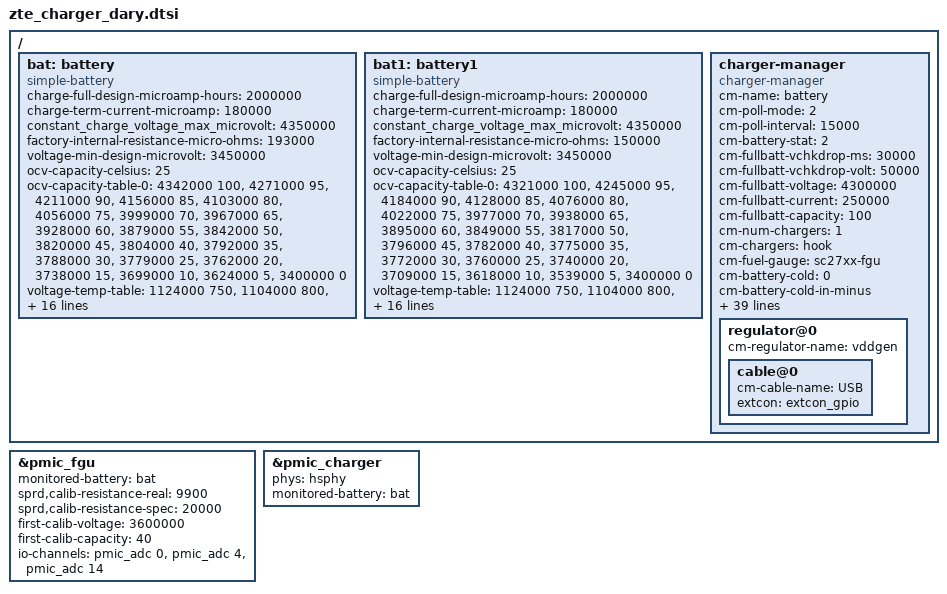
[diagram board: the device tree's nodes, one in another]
/ {
	bat: battery {
		compatible = "simple-battery";
		charge-full-design-microamp-hours = <2000000>;
		charge-term-current-microamp = <120000>;
		constant_charge_voltage_max_microvolt = <4350000>;
		factory-internal-resistance-micro-ohms = <320000>;
		voltage-min-design-microvolt = <3450000>;
		ocv-capacity-celsius = <20>;
		ocv-capacity-table-0 = <4330000 100>, <4249000 95>, <4189000 90>,
					<4133000 85>, <4081000 80>, <4034000 75>,
					<3991000 70>, <3953000 65>, <3910000 60>,
					<3866000 55>, <3836000 50>, <3813000 45>,
					<3795000 40>, <3782000 35>, <3774000 30>,
					<3765000 25>, <3750000 20>, <3726000 15>,
					<3687000 10>, <3658000 5>, <3400000 0>;
		voltage-temp-table = <1124000 750>, <1104000 800>, <1079000 850>,
					<1047000 900>, <1010000 950>, <967000 1000>,
					<917000 1050>, <861000 1100>, <801000 1150>,
					<738000 1200>, <672000 1250>, <607000 1300>,
					<543000 1350>, <482000 1400>, <425000 1450>,
					<372000 1500>, <325000 1550>, <282000 1600>,
					<243000 1650>, <208000 1700>, <178000 1750>;
		capacity-temp-table = <25 100>, <10 97>, <(-10) 60>;
		resistance-temp-table = <20 100>, <10 243>, <(-10) 468>;
		charge-sdp-current-microamp = <500000 500000>;
		charge-dcp-current-microamp = <1150000 3000000>;
		charge-cdp-current-microamp = <1150000 1150000>;
		charge-unknown-current-microamp = <500000 500000>;
	};

	bat1: battery1 {
		compatible = "simple-battery";
		charge-full-design-microamp-hours = <2000000>;
		charge-term-current-microamp = <120000>;
		constant_charge_voltage_max_microvolt = <4350000>;
		factory-internal-resistance-micro-ohms = <320000>;
		voltage-min-design-microvolt = <3450000>;
		ocv-capacity-celsius = <20>;
		ocv-capacity-table-0 = <4330000 100>, <4249000 95>, <4189000 90>,
					<4133000 85>, <4081000 80>, <4034000 75>,
					<3991000 70>, <3953000 65>, <3910000 60>,
					<3866000 55>, <3836000 50>, <3813000 45>,
					<3795000 40>, <3782000 35>, <3774000 30>,
					<3765000 25>, <3750000 20>, <3726000 15>,
					<3687000 10>, <3658000 5>, <3400000 0>;
		voltage-temp-table = <1124000 750>, <1104000 800>, <1079000 850>,
					<1047000 900>, <1010000 950>, <967000 1000>,
					<917000 1050>, <861000 1100>, <801000 1150>,
					<738000 1200>, <672000 1250>, <607000 1300>,
					<543000 1350>, <482000 1400>, <425000 1450>,
					<372000 1500>, <325000 1550>, <282000 1600>,
					<243000 1650>, <208000 1700>, <178000 1750>;
		capacity-temp-table = <25 100>, <10 97>, <(-10) 60>;
		resistance-temp-table = <20 100>, <10 243>, <(-10) 468>;
		charge-sdp-current-microamp = <500000 500000>;
		charge-dcp-current-microamp = <1150000 3000000>;
		charge-cdp-current-microamp = <1150000 1150000>;
		charge-unknown-current-microamp = <500000 500000>;
	};

	charger-manager {
		compatible = "charger-manager";
		cm-name = "battery";
		cm-poll-mode = <2>;
		cm-poll-interval = <15000>;
		cm-battery-stat = <2>;

		cm-fullbatt-vchkdrop-ms = <30000>;
		cm-fullbatt-vchkdrop-volt = <60000>;
		cm-fullbatt-voltage = <4330000>;
		cm-fullbatt-current = <120000>;
		cm-fullbatt-capacity = <100>;

		cm-num-chargers = <1>;
		cm-chargers = "fan54015_charger";
		cm-fuel-gauge = "sc27xx-fgu";

		/* in deci centigrade */
		cm-battery-cold = <200>;
		cm-battery-cold-in-minus;
		cm-battery-hot = <800>;
		cm-battery-temp-diff = <100>;

		/* Allow charging for 6hr */
		cm-charging-max = <21600000>;
		/* recovery charging after stop charging 45min */
		cm-discharging-max = <2700000>;

		/* the interval to feed charger watchdog */
		cm-wdt-interval = <60>;

		/* drop voltage in microVolts to allow shutdown */
		cm-shutdown-voltage = <3100000>;

		/* when 99% of the time is exceeded, it will be forced to 100% */
		cm-tickle-time-out = <1500>;

		/* how much time to allow capacity change */
		cm-one-cap-time = <30>;

		/* when the safe charging voltage is exceeded, stop charging */
		cm-charge-voltage-max = <6500000>;
		/* drop voltage in microVolts to restart charging */
		cm-charge-voltage-drop = <700000>;
		cm-dcp-jeita-temp-table = <1000 1030 0 4350000>, <1150 1180 700000 4350000>,
			<1450 1420 1150000 4350000>, <1600 1570 700000 4100000>;
		cm-sdp-jeita-temp-table = <1000 1030 0 4350000>, <1150 1180 500000 4350000>,
			<1450 1420 500000 4350000>, <1600 1570 500000 4100000>;
		cm-cdp-jeita-temp-table = <1000 1030 0 4350000>, <1150 1180 700000 4350000>,
			<1450 1420 1150000 4350000>, <1600 1570 700000 4100000>;
		cm-unknown-jeita-temp-table = <1000 1030 0 4350000>, <1150 1180 500000 4350000>,
			<1450 1420 500000 4350000>, <1600 1570 500000 4100000>;

		monitored-battery = <&bat>;
		cm-capacity-track;

		cm-cap-remap-table = <1 2 3>, <2 3 2>, <98 99 2>, <99 100 3>;

		regulator@0 {
			cm-regulator-name = "vddgen";
			cable@0 {
				cm-cable-name = "USB";
				extcon = <&extcon_gpio>;
			};
		};
	};
};

&bat {
	charge-full-design-microamp-hours = <2000000>;
	charge-term-current-microamp = <180000>;
	constant_charge_voltage_max_microvolt = <4350000>;
	constant_charge_current_max_microamp = <1000000>;
	factory-internal-resistance-micro-ohms = <193000>;
	voltage-min-design-microvolt = <3450000>;
	ocv-capacity-celsius = <25>;
	batt-id-list = <270>;  /* kohm, fenghua / weike */
	ocv-capacity-table-0 = <4342000 100>, <4271000 95>, <4211000 90>,
				<4156000 85>, <4103000 80>, <4056000 75>,
				<3999000 70>, <3967000 65>, <3928000 60>,
				<3879000 55>, <3842000 50>, <3820000 45>,
				<3804000 40>, <3792000 35>, <3788000 30>,
				<3779000 25>, <3762000 20>, <3738000 15>,
				<3699000 10>, <3624000 5>, <3400000 0>;
	/* NTC 100k, Vref 1850mV, R pull-up 110K, R pull-down 200k */
	voltage-temp-table = <1124000 750>, <1104000 800>, <1079000 850>,
				<1047000 900>, <1010000 950>, <967000 1000>,
				<917000 1050>, <861000 1100>, <801000 1150>,
				<738000 1200>, <672000 1250>, <607000 1300>,
				<543000 1350>, <482000 1400>, <425000 1450>,
				<372000 1500>, <325000 1550>, <282000 1600>,
				<243000 1650>, <208000 1700>, <178000 1750>;
	charge-sdp-current-microamp = <500000 500000>;
	charge-dcp-current-microamp = <1000000 1000000>;
	charge-cdp-current-microamp = <1000000 1000000>;
	charge-unknown-current-microamp = <500000 500000>;
};

&bat1 {
	charge-full-design-microamp-hours = <2000000>;
	charge-term-current-microamp = <180000>;
	constant_charge_voltage_max_microvolt = <4350000>;
	constant_charge_current_max_microamp = <1000000>;
	factory-internal-resistance-micro-ohms = <150000>;
	voltage-min-design-microvolt = <3450000>;
	ocv-capacity-celsius = <25>;
	batt-id-list = <270>;  /* kohm, fenghua / weike */
	ocv-capacity-table-0 = <4321000 100>, <4245000 95>, <4184000 90>,
				<4128000 85>, <4076000 80>, <4022000 75>,
				<3977000 70>, <3938000 65>, <3895000 60>,
				<3849000 55>, <3817000 50>, <3796000 45>,
				<3782000 40>, <3775000 35>, <3772000 30>,
				<3760000 25>, <3740000 20>, <3709000 15>,
				<3618000 10>, <3539000 5>, <3400000 0>;
	/* NTC 100k, Vref 1850mV, R pull-up 110K, R pull-down 200k */
	voltage-temp-table = <1124000 750>, <1104000 800>, <1079000 850>,
				<1047000 900>, <1010000 950>, <967000 1000>,
				<917000 1050>, <861000 1100>, <801000 1150>,
				<738000 1200>, <672000 1250>, <607000 1300>,
				<543000 1350>, <482000 1400>, <425000 1450>,
				<372000 1500>, <325000 1550>, <282000 1600>,
				<243000 1650>, <208000 1700>, <178000 1750>;
	charge-sdp-current-microamp = <500000 500000>;
	charge-dcp-current-microamp = <1000000 1000000>;
	charge-cdp-current-microamp = <1000000 1000000>;
	charge-unknown-current-microamp = <500000 500000>;
};

&pmic_fgu {
	monitored-battery = <&bat>;
	sprd,calib-resistance-real = <9900>;
	sprd,calib-resistance-spec = <20000>;
	first-calib-voltage = <3600000>;
	first-calib-capacity = <40>;
	io-channels = <&pmic_adc 0>, <&pmic_adc 4>, <&pmic_adc 14>;
	io-channel-names = "adc-batt-id", "bat-temp", "charge-vol";
};

/ {
	charger-manager {
		cm-fullbatt-voltage = <4300000>;
		cm-fullbatt-vchkdrop-volt = <50000>;
		cm-fullbatt-current = <250000>;

		/* in deci centigrade */
		cm-battery-cold = <0>;
		cm-battery-hot = <550>;
		cm-battery-temp-diff = <30>;
		cm-tickle-time-out = <180>;

		cm-disable-charger-type-jeita;
		cm-jeita-temp-table = <1000 1030 0 4350000>,
				<1050 1080 600000 4350000>,
				<1150 1180 600000 4350000>,
				<1450 1420 1000000 4350000>,
				<1550 1520 600000 4100000>;

		cm-chargers = "hook";
		cm-hardware-psy = "sc2720_charger";
		monitored-battery =<&bat>;
		phys = <&hsphy>;
	};
};

&pmic_charger {
	status = "okay";
	phys = <&hsphy>;
	monitored-battery = <&bat>;
};

#include "../bat_setting/battery_protect_policy_080500100347.dtsi"
